# STM32MP21_CA35 register map
File version: 0.4
CPU: CM33 r0p1, little endian, MPU, FPU, vendor SysTick, 8 interrupt priority bits
Registers are 32-bit, read-write, reset 0x0 unless marked. A register's access mark holds for its fields unless they carry their own. Offsets are from the block's base; [hi:lo] are bit positions; {n}, {i} and the like mark numbered series.

## SPDIFRX — SPDIFRX address block description
Base 0x400D0000
Same registers: SPDIFRX_S 0x500D0000
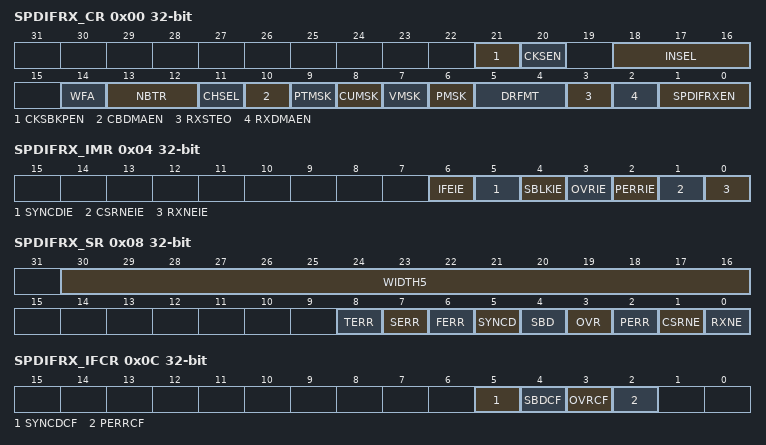
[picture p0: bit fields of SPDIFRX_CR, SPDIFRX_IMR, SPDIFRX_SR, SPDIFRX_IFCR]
0x00 SPDIFRX_CR — SPDIFRX control register
  [21] CKSBKPEN — Backup symbol clock enable
    1=The SPDIFRX generates a backup symbol clock if CKSEN = 1; 0=The SPDIFRX does not generate a backup symbol clock
  [20] CKSEN — Symbol clock enable
    1=The SPDIFRX generates a symbol clock; 0=The SPDIFRX does not generate a symbol clock
  [18:16] INSEL — SPDIFRX input selection
    {v}=SPDIFRX_IN{v} selected (v=0..3)
  [14] WFA — Wait for activityless thansup>(1)less than/sup>
    1=The SPDIFRX waits for activity on SPDIFRX_IN line (4 transitions) before performing the synchronization; 0=The SPDIFRX does not wait for activity on SPDIFRX_IN line before performing the synchronization
  [13:12] NBTR — Maximum allowed re-tries during synchronization phaseless thansup>(1)less than/sup>
    0=No re-try is allowed (only one attempt); 1=3 re-tries allowed; 2=15 re-tries allowed; 3=63 re-tries allowed
  [11] CHSEL — Channel selectionless thansup>(1)less than/sup>
    1=The control flow takes the channel status from channel B; 0=The control flow takes the channel status from channel A
  [10] CBDMAEN — Control buffer DMA enable for control flowless thansup>(1)less than/sup>
    1=DMA mode is enabled for reception of channel status and used data information; 0=DMA mode is disabled for reception of channel status and used data information
  [9] PTMSK — Mask of preamble type bitsless thansup>(1)less than/sup>
    1=The preamble type bits are not copied into the SPDIFRX_FMTx_DR, zeros are written instead; 0=The preamble type bits are copied into the SPDIFRX_FMTx_DR
  [8] CUMSK — Mask of channel status and user bitsless thansup>(1)less than/sup>
    1=The channel status and user bits are not copied into the SPDIFRX_FMTx_DR, zeros are written instead; 0=The channel status and user bits are copied into the SPDIFRX_FMTx_DR
  [7] VMSK — Mask of validity bitless thansup>(1)less than/sup>
    1=The validity bit is not copied into the SPDIFRX_FMTx_DR, a zero is written instead; 0=The validity bit is copied into the SPDIFRX_FMTx_DR
  [6] PMSK — Mask parity error bitless thansup>(1)less than/sup>
    1=The parity error bit is not copied into the SPDIFRX_FMTx_DR, a zero is written instead; 0=The parity error bit is copied into the SPDIFRX_FMTx_DR
  [5:4] DRFMT — RX data formatless thansup>(1)less than/sup>
    2=Data sample are packed by setting two 16-bit sample into a 32-bit word; 1=Data samples are aligned in the left (MSB); 0=Data samples are aligned in the right (LSB)
  [3] RXSTEO — Stereo modeless thansup>(1)less than/sup>
    1=The peripheral is in stereo mode; 0=The peripheral is in mono mode
  [2] RXDMAEN — Receiver DMA enable for data flowless thansup>(1)less than/sup>
    1=DMA mode is enabled for reception; 0=DMA mode is disabled for reception
  [1:0] SPDIFRXEN — Peripheral block enableless thansup>(1)less than/sup>
    0=Disable SPDIFRX (STATE_IDLE); 1=Enable SPDIFRX synchronization only; 3=Enable SPDIF receiver
0x04 SPDIFRX_IMR — SPDIFRX interrupt mask register
  [6] IFEIE — Serial interface error interrupt enable
    0=Interrupt is inhibited; 1=A SPDIFRX interface interrupt is generated whenever SERR = 1, TERR = 1, or FERR = 1 in theSPDIFRX_SR register
  [5] SYNCDIE — Synchronization done
    0=Interrupt is inhibited; 1=A SPDIFRX interface interrupt is generated whenever SYNCD = 1 in the SPDIFRX_SR register
  [4] SBLKIE — Synchronization block detected interrupt enable
    0=Interrupt is inhibited; 1=A SPDIFRX interface interrupt is generated whenever SBD = 1 in the SPDIFRX_SR register
  [3] OVRIE — Overrun error interrupt enable
    0=Interrupt is inhibited; 1=A SPDIFRX interface interrupt is generated whenever OVR=1 in the SPDIFRX_SR register
  [2] PERRIE — Parity error interrupt enable
    0=Interrupt is inhibited; 1=A SPDIFRX interface interrupt is generated whenever PERR=1 in the SPDIFRX_SR register
  [1] CSRNEIE — Control buffer ready interrupt enable
    0=Interrupt is inhibited; 1=A SPDIFRX interface interrupt is generated whenever CSRNE = 1 in the SPDIFRX_SR register
  [0] RXNEIE — RXNE interrupt enable
    0=Interrupt is inhibited; 1=A SPDIFRX interface interrupt is generated whenever RXNE=1 in the SPDIFRX_SR register
0x08 SPDIFRX_SR ro — SPDIFRX status register
  [30:16] WIDTH5 — duration of 5 symbols counted with spdifrx_ker_ck
  [8] TERR — Time-out error
    0=No sequence error is detected; 1=Sequence error is detected
  [7] SERR — Synchronization error
    0=No synchronization error is detected; 1=Synchronization error is detected
  [6] FERR — Framing error
    0=No Manchester violation detected; 1=Manchester violation detected
  [5] SYNCD — Synchronization done
    0=Synchronization is pending; 1=Synchronization is completed
  [4] SBD — Synchronization block detected
    0=No B preamble is detected; 1=B preamble is detected
  [3] OVR — Overrun error
    0=No overrun error; 1=Overrun error is detected
  [2] PERR — Parity error
    0=No parity error; 1=Parity error
  [1] CSRNE — Control buffer register not empty
    0=No control word available on SPDIFRX_CSR register; 1=A control word is available on SPDIFRX_CSR register
  [0] RXNE — Read data register not empty
    0=Data is not received; 1=Received data is ready to be read
0x0C SPDIFRX_IFCR wo — SPDIFRX interrupt flag clear register
  [5] SYNCDCF — clears the synchronization done flag
  [4] SBDCF — clears the synchronization block detected flag
  [3] OVRCF — clears the overrun error flag
  [2] PERRCF — clears the parity error flag
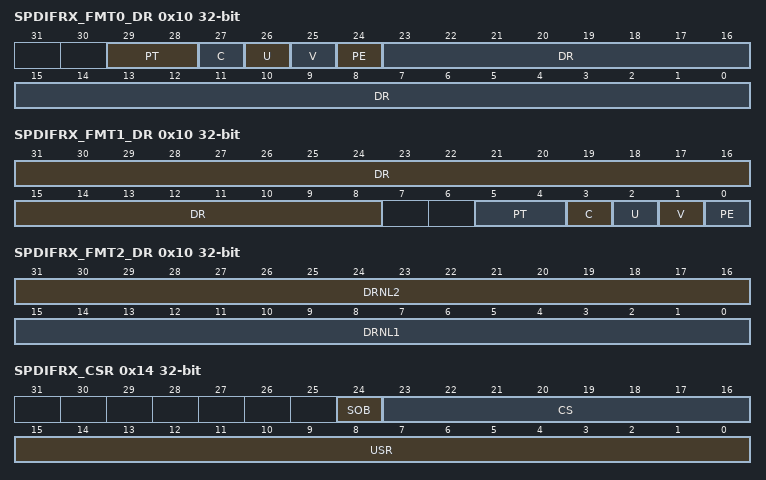
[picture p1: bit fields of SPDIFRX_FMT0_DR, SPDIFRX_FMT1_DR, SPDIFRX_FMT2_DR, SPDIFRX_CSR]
0x10 SPDIFRX_FMT0_DR ro — SPDIFRX data input register
  [29:28] PT — preamble type
    1=Preamble B received; 2=Preamble M received; 3=Preamble W received
  [27] C — channel status bit
  [26] U — user bit
  [25] V — validity bit
  [24] PE — parity error bit
  [23:0] DR — data value
0x10 SPDIFRX_FMT1_DR ro (alternate view of SPDIFRX_FMT0_DR) — SPDIFRX data input register
  [31:8] DR — data value
  [5:4] PT — preamble type
    1=preamble B received; 2=preamble M received; 3=preamble W received
  [3] C — channel Status bit
  [2] U — user bit
  [1] V — validity bit
  [0] PE — parity error bit
0x10 SPDIFRX_FMT2_DR ro (alternate view of SPDIFRX_FMT0_DR) — SPDIFRX data input register
  [31:16] DRNL2 — data value
  [15:0] DRNL1 — data value
0x14 SPDIFRX_CSR ro — SPDIFRX channel status register
  [24] SOB — start of block
    0=CS[0] is not the first bit of a new block; 1=CS[0] is the first bit of a new block
  [23:16] CS — channel A status information
  [15:0] USR — user data information
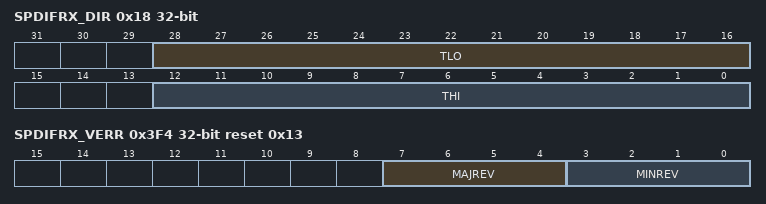
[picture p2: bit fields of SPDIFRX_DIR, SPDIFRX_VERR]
0x18 SPDIFRX_DIR ro — SPDIFRX debug information register
  [28:16] TLO — threshold LOW (TLO = 1.
  [12:0] THI — threshold HIGH (THI = 2.
0x3F4 SPDIFRX_VERR ro reset 0x13 — SPDIFRX version register
  [7:4] MAJREV — SPDIFRX major revision
  [3:0] MINREV — SPDIFRX minor revision
0x3F8 SPDIFRX_IPIDR ro reset 0x130041 — SPDIFRX identification register
  [31:0] ID — SPDIFRX identifier
0x3FC SPDIFRX_SIDR ro reset 0xA3C5DD01 — SPDIFRX size identification register
  [31:0] SID — Size identification
